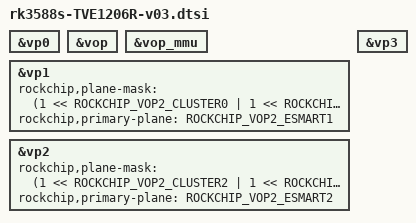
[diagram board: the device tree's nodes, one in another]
// SPDX-License-Identifier: (GPL-2.0+ OR MIT)
/*
 * Copyright (c) 2021 Rockchip Electronics Co., Ltd.
 *
 */

#include "dt-bindings/usb/pd.h"
#include "rk3588s.dtsi"
#include "rk3588s-TVE1206R.dtsi"
#include "rk3588-rk806-single.dtsi"
#include "rk3588-MIPI-TS125QDM-LW1-68P0-TVE1206R.dtsi"
#include "rk3588s-TVE1206R-wifibt.dtsi"
#include "rk3588s-TVE1206R-audio.dtsi"
#include "rk3588s-TVE1206R-camera.dtsi"

/* vp0 & vp3 are not used on this board */
&vp0 {
	/delete-property/ rockchip,plane-mask;
	/delete-property/ rockchip,primary-plane;
};

&vop {
	status = "okay";
};

&vop_mmu {
	status = "okay";
};

&vp1 {
	rockchip,plane-mask = <(1 << ROCKCHIP_VOP2_CLUSTER0 | 1 << ROCKCHIP_VOP2_ESMART0 |
				1 << ROCKCHIP_VOP2_CLUSTER1 | 1 << ROCKCHIP_VOP2_ESMART1)>;
	rockchip,primary-plane = <ROCKCHIP_VOP2_ESMART1>;
};

&vp2 {
	rockchip,plane-mask = <(1 << ROCKCHIP_VOP2_CLUSTER2 | 1 << ROCKCHIP_VOP2_ESMART2 |
				1 << ROCKCHIP_VOP2_CLUSTER3 | 1 << ROCKCHIP_VOP2_ESMART3)>;
	rockchip,primary-plane = <ROCKCHIP_VOP2_ESMART2>;
};

&vp3 {
	/delete-property/ rockchip,plane-mask;
	/delete-property/ rockchip,primary-plane;
};
